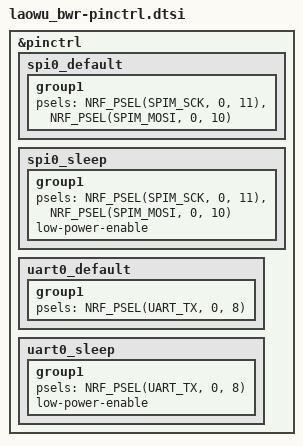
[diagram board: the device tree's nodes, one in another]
/*
 * Copyright (c) 2026 Cremind
 * SPDX-License-Identifier: MIT
 *
 * Pins from hardware/matrix.yaml (laowu_bwr), decimal port-0 numbers.
 */

&pinctrl {
	spi0_default: spi0_default {
		group1 {
			psels = <NRF_PSEL(SPIM_SCK, 0, 11)>,
				<NRF_PSEL(SPIM_MOSI, 0, 10)>;
		};
	};

	spi0_sleep: spi0_sleep {
		group1 {
			psels = <NRF_PSEL(SPIM_SCK, 0, 11)>,
				<NRF_PSEL(SPIM_MOSI, 0, 10)>;
			low-power-enable;
		};
	};

	uart0_default: uart0_default {
		group1 {
			psels = <NRF_PSEL(UART_TX, 0, 8)>;
		};
	};

	uart0_sleep: uart0_sleep {
		group1 {
			psels = <NRF_PSEL(UART_TX, 0, 8)>;
			low-power-enable;
		};
	};
};
